AUTOSAR XML (schema 4-2-2)
package /ETAS_BIP_TSTM/SwComponentTypes
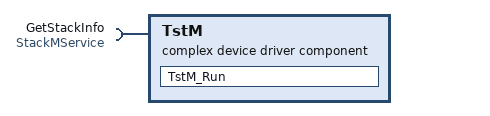
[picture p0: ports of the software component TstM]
  complex device driver sw component type TstM
    require port GetStackInfo: required-interface=StackMService
    behavior IntBeh_TstM
      runnable TstM_Run
        sync call SSCP_GetStackInfo: operation=GetStackInfo.GetStackInfo
package /ETAS_BIP_TSTM/SwcImplementations
  swc implementation Impl_TstM: programming-language=C, sw-version=1.0.0, swc-bsw-mapping=SwcBswMapping, vendor-id=11, behavior=IntBeh_TstM
    code-descriptors:
      code CodeDescr_TstM: artifact-descriptors=autosar-engineering-object={short-label=Code_0, category=SWSRC}
package /ETAS_BIP_TSTM/SwcBswMappings
  swc bsw mapping SwcBswMapping: bsw-behavior=BswInternalBehavior, swc-bsw-runnable-mapping{bsw-entity=TstM_Run, swc-runnable=TstM_Run}, swc-behavior=IntBeh_TstM
